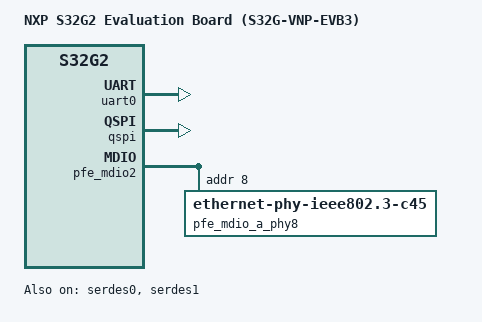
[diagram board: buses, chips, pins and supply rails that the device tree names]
// SPDX-License-Identifier: GPL-2.0-or-later OR MIT
/*
 * Copyright 2019-2021, 2024 NXP
 */

/dts-v1/;

#include "s32g2.dtsi"
#include "s32gxxxa-evb.dtsi"

/ {
	model = "NXP S32G2 Evaluation Board (S32G-VNP-EVB3)";
	compatible = "nxp,s32g274a-evb3", "nxp,s32g2";
};

/* UART (J58) to Micro USB port */
&uart0 {
	status = "okay";
};

&qspi {
	status = "okay";
};

&serdes0 {
	status = "okay";
};

&serdes1 {
	status = "okay";
};

&pfe_mdio2 {
	/* AQR113 on S32G-PROCEVB3-S */
	pfe_mdio_a_phy8: ethernet-phy@8 {
		compatible = "ethernet-phy-ieee802.3-c45";
		reg = <8>;
	};
};

&pfe_netif0 {
	phy-mode = "sgmii";
	phy-handle = <&pfe_mdio_a_phy8>;
};
